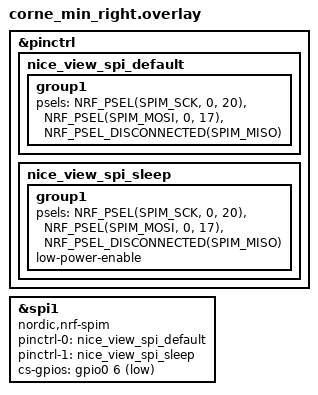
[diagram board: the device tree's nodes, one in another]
#include <zephyr/dt-bindings/pinctrl/nrf-pinctrl.h>

/* Pinctrl setup for the SPIM instance we’ll use for nice!view */
&pinctrl {
    nice_view_spi_default: nice_view_spi_default {
        group1 {
            psels = <NRF_PSEL(SPIM_SCK, 0, 20)>,
                    <NRF_PSEL(SPIM_MOSI, 0, 17)>,
                    <NRF_PSEL_DISCONNECTED(SPIM_MISO)>;
        };
    };

    nice_view_spi_sleep: nice_view_spi_sleep {
        group1 {
            psels = <NRF_PSEL(SPIM_SCK, 0, 20)>,
                    <NRF_PSEL(SPIM_MOSI, 0, 17)>,
                    <NRF_PSEL_DISCONNECTED(SPIM_MISO)>;
            low-power-enable;
        };
    };
};

/*
 * Provide the label the nice_view_gem overlay expects:
 * &nice_view_spi
 *
 * We point it at spi0 (SPIM0). If your board already uses spi0 for something,
 * switch this to &spi1 instead.
 */
nice_view_spi: &spi1 {
    status = "okay";
    compatible = "nordic,nrf-spim";

    pinctrl-0 = <&nice_view_spi_default>;
    pinctrl-1 = <&nice_view_spi_sleep>;
    pinctrl-names = "default", "sleep";

    /* nice!view recommended CS pin: P0.06 */
    cs-gpios = <&gpio0 6 GPIO_ACTIVE_LOW>;
};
